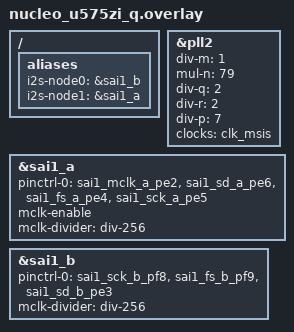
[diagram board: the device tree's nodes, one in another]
/ {
	aliases {
		i2s-node0 = &sai1_b;
		i2s-node1 = &sai1_a;
	};
};

&pll2 {
	/* 44.1KHz (-0.03% Error) */
	div-m = <1>;
	mul-n = <79>;
	div-q = <2>;
	div-r = <2>;
	div-p = <7>;
	clocks = <&clk_msis>;
	status = "okay";
};

/* Master Transmit */
&sai1_a {
	pinctrl-0 = <&sai1_mclk_a_pe2 &sai1_sd_a_pe6
		     &sai1_fs_a_pe4 &sai1_sck_a_pe5>;
	pinctrl-names = "default";
	status = "okay";
	mclk-enable;
	mclk-divider = "div-256";
	dma-names = "tx";
};

/* Slave Receive */
&sai1_b {
	pinctrl-0 = <&sai1_sck_b_pf8 &sai1_fs_b_pf9 &sai1_sd_b_pe3>;
	pinctrl-names = "default";
	status = "okay";
	mclk-divider = "div-256";
	dma-names = "rx";
};
